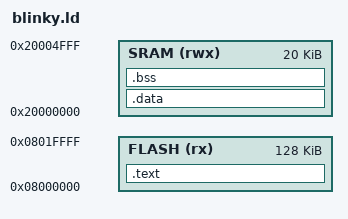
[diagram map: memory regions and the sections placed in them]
MEMORY
{
  FLASH (rx) : ORIGIN = 0x08000000, LENGTH = 128K
  SRAM (rwx) : ORIGIN = 0x20000000, LENGTH = 20K
}

SECTIONS
{
    .text :
    {
        _text = .;
        KEEP(*(.isr_vector))
        *(.text*)
        *(.rodata*)
        _etext = .;
    } > FLASH

    .data : AT(ADDR(.text) + SIZEOF(.text))
    {
        _data = .;
        *(vtable)
        *(.data*)
        _edata = .;
    } > SRAM

    .bss :
    {
        _bss = .;
        *(.bss*)
        *(COMMON)
        _ebss = .;
    } > SRAM
}
